# COMPUTE_CLUSTER_J7AHP0_CFG_WRAP_0_VBUSP4_CFG_AW4_CFG_MSMC1_ECC0 register map
Vendor: Texas Instruments
Peripheral module from a debugger description file (folder J7_AHP).
Registers are 32-bit, access not given, reset 0x0 unless marked. A register's access mark holds for its fields unless they carry their own. Offsets are as the file gives them; lines under a group give offsets from that group; [hi:lo] are bit positions; {n}, {i} and the like mark numbered series; 'fields as' and 'values as' point back to an identical list; <NAME> marks a mode.

## COMPUTE_CLUSTER_J7AHP0_CFG_WRAP_0_VBUSP4_CFG_AW4_CFG_MSMC1_ECC0
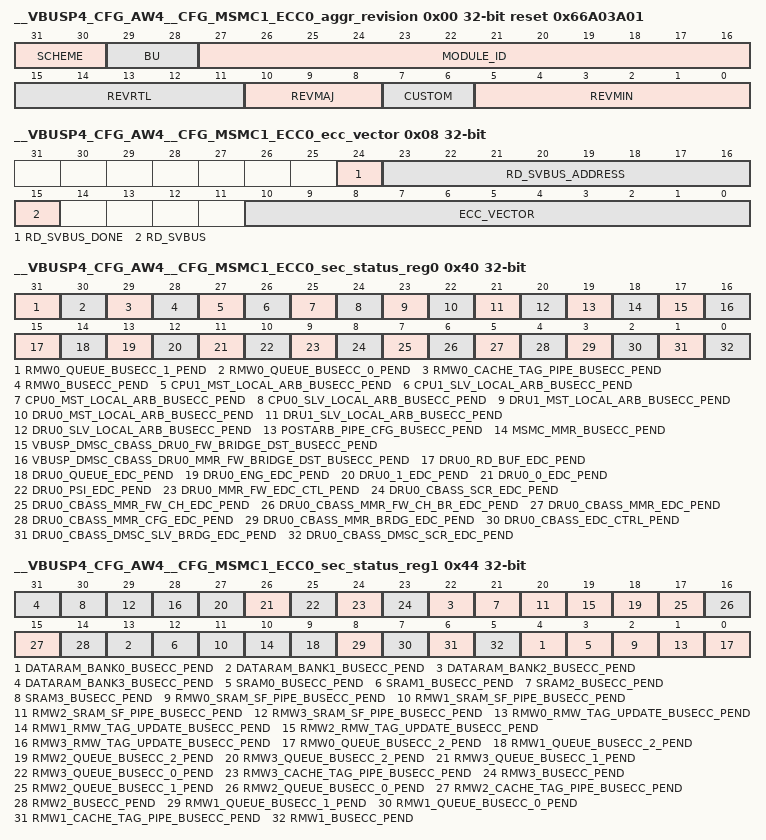
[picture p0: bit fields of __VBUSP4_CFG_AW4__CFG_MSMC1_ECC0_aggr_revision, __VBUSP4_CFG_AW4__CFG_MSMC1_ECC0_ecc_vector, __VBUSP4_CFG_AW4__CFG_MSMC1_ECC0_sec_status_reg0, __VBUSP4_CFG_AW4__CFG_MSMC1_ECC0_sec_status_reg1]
0x00 __VBUSP4_CFG_AW4__CFG_MSMC1_ECC0_aggr_revision ro reset 0x66A03A01
  [31:30] SCHEME
  [29:28] BU
  [27:16] MODULE_ID
  [15:11] REVRTL — RTL version
  [10:8] REVMAJ — Major version
  [7:6] CUSTOM — Custom version
  [5:0] REVMIN — Minor version
0x08 __VBUSP4_CFG_AW4__CFG_MSMC1_ECC0_ecc_vector
  [24] RD_SVBUS_DONE — Status to indicate if read on serial VBUS is complete, write of any value will clear this bit. (access R/W1TC)
  [23:16] RD_SVBUS_ADDRESS rw — Read address
  [15] RD_SVBUS — Write 1 to trigger a read on the serial VBUS (access R/W1TS)
  [10:0] ECC_VECTOR rw — Value written to select the corresponding ECC RAM for control or status
0x0C __VBUSP4_CFG_AW4__CFG_MSMC1_ECC0_misc_status ro reset 0x44
  [10:0] NUM_RAMS — Indicates the number of RAMS serviced by the ECC aggregator
0x10 __VBUSP4_CFG_AW4__CFG_MSMC1_ECC0_reserved_svbus rw
  [31:0] DATA — Serial VBUS register data
0x3C __VBUSP4_CFG_AW4__CFG_MSMC1_ECC0_sec_eoi_reg
  [0] EOI_WR — EOI Register (access R/W1TS)
0x40 __VBUSP4_CFG_AW4__CFG_MSMC1_ECC0_sec_status_reg0
  [31] RMW0_QUEUE_BUSECC_1_PEND — Interrupt Pending Status for rmw0_queue_busecc_1_pend (access R/W1TS)
  [30] RMW0_QUEUE_BUSECC_0_PEND — Interrupt Pending Status for rmw0_queue_busecc_0_pend (access R/W1TS)
  [29] RMW0_CACHE_TAG_PIPE_BUSECC_PEND — Interrupt Pending Status for rmw0_cache_tag_pipe_busecc_pend (access R/W1TS)
  [28] RMW0_BUSECC_PEND — Interrupt Pending Status for rmw0_busecc_pend (access R/W1TS)
  [27] CPU1_MST_LOCAL_ARB_BUSECC_PEND — Interrupt Pending Status for cpu1_mst_local_arb_busecc_pend (access R/W1TS)
  [26] CPU1_SLV_LOCAL_ARB_BUSECC_PEND — Interrupt Pending Status for cpu1_slv_local_arb_busecc_pend (access R/W1TS)
  [25] CPU0_MST_LOCAL_ARB_BUSECC_PEND — Interrupt Pending Status for cpu0_mst_local_arb_busecc_pend (access R/W1TS)
  [24] CPU0_SLV_LOCAL_ARB_BUSECC_PEND — Interrupt Pending Status for cpu0_slv_local_arb_busecc_pend (access R/W1TS)
  [23] DRU1_MST_LOCAL_ARB_BUSECC_PEND — Interrupt Pending Status for dru1_mst_local_arb_busecc_pend (access R/W1TS)
  [22] DRU0_MST_LOCAL_ARB_BUSECC_PEND — Interrupt Pending Status for dru0_mst_local_arb_busecc_pend (access R/W1TS)
  [21] DRU1_SLV_LOCAL_ARB_BUSECC_PEND — Interrupt Pending Status for dru1_slv_local_arb_busecc_pend (access R/W1TS)
  [20] DRU0_SLV_LOCAL_ARB_BUSECC_PEND — Interrupt Pending Status for dru0_slv_local_arb_busecc_pend (access R/W1TS)
  [19] POSTARB_PIPE_CFG_BUSECC_PEND — Interrupt Pending Status for postarb_pipe_cfg_busecc_pend (access R/W1TS)
  [18] MSMC_MMR_BUSECC_PEND — Interrupt Pending Status for msmc_mmr_busecc_pend (access R/W1TS)
  [17] VBUSP_DMSC_CBASS_DRU0_FW_BRIDGE_DST_BUSECC_PEND — Interrupt Pending Status for vbusp_dmsc_cbass_dru0_fw_bridge_dst_busecc_pend (access R/W1TS)
  [16] VBUSP_DMSC_CBASS_DRU0_MMR_FW_BRIDGE_DST_BUSECC_PEND — Interrupt Pending Status for vbusp_dmsc_cbass_dru0_mmr_fw_bridge_dst_busecc_pend (access R/W1TS)
  [15] DRU0_RD_BUF_EDC_PEND — Interrupt Pending Status for dru0_rd_buf_edc_pend (access R/W1TS)
  [14] DRU0_QUEUE_EDC_PEND — Interrupt Pending Status for dru0_queue_edc_pend (access R/W1TS)
  [13] DRU0_ENG_EDC_PEND — Interrupt Pending Status for dru0_eng_edc_pend (access R/W1TS)
  [12] DRU0_1_EDC_PEND — Interrupt Pending Status for dru0_1_edc_pend (access R/W1TS)
  [11] DRU0_0_EDC_PEND — Interrupt Pending Status for dru0_0_edc_pend (access R/W1TS)
  [10] DRU0_PSI_EDC_PEND — Interrupt Pending Status for dru0_psi_edc_pend (access R/W1TS)
  [9] DRU0_MMR_FW_EDC_CTL_PEND — Interrupt Pending Status for dru0_mmr_fw_edc_ctl_pend (access R/W1TS)
  [8] DRU0_CBASS_SCR_EDC_PEND — Interrupt Pending Status for dru0_cbass_scr_edc_pend (access R/W1TS)
  [7] DRU0_CBASS_MMR_FW_CH_EDC_PEND — Interrupt Pending Status for dru0_cbass_mmr_fw_ch_edc_pend (access R/W1TS)
  [6] DRU0_CBASS_MMR_FW_CH_BR_EDC_PEND — Interrupt Pending Status for dru0_cbass_mmr_fw_ch_br_edc_pend (access R/W1TS)
  [5] DRU0_CBASS_MMR_EDC_PEND — Interrupt Pending Status for dru0_cbass_mmr_edc_pend (access R/W1TS)
  [4] DRU0_CBASS_MMR_CFG_EDC_PEND — Interrupt Pending Status for dru0_cbass_mmr_cfg_edc_pend (access R/W1TS)
  [3] DRU0_CBASS_MMR_BRDG_EDC_PEND — Interrupt Pending Status for dru0_cbass_mmr_brdg_edc_pend (access R/W1TS)
  [2] DRU0_CBASS_EDC_CTRL_PEND — Interrupt Pending Status for dru0_cbass_edc_ctrl_pend (access R/W1TS)
  [1] DRU0_CBASS_DMSC_SLV_BRDG_EDC_PEND — Interrupt Pending Status for dru0_cbass_dmsc_slv_brdg_edc_pend (access R/W1TS)
  [0] DRU0_CBASS_DMSC_SCR_EDC_PEND — Interrupt Pending Status for dru0_cbass_dmsc_scr_edc_pend (access R/W1TS)
0x44 __VBUSP4_CFG_AW4__CFG_MSMC1_ECC0_sec_status_reg1
  [9n+4] DATARAM_BANK{n}_BUSECC_PEND (n=0..3) — Interrupt Pending Status for dataram_bank{n}_busecc_pend (access R/W1TS)
  [9n+3] SRAM{n}_BUSECC_PEND (n=0..3) — Interrupt Pending Status for sram{n}_busecc_pend (access R/W1TS)
  [9n+2] RMW{n}_SRAM_SF_PIPE_BUSECC_PEND (n=0..3) — Interrupt Pending Status for rmw{n}_sram_sf_pipe_busecc_pend (access R/W1TS)
  [9n+1] RMW{n}_RMW_TAG_UPDATE_BUSECC_PEND (n=0..3) — Interrupt Pending Status for rmw{n}_rmw_tag_update_busecc_pend (access R/W1TS)
  [9n] RMW{n}_QUEUE_BUSECC_2_PEND (n=0..3) — Interrupt Pending Status for rmw{n}_queue_busecc_2_pend (access R/W1TS)
  [26] RMW3_QUEUE_BUSECC_1_PEND — Interrupt Pending Status for rmw3_queue_busecc_1_pend (access R/W1TS)
  [25] RMW3_QUEUE_BUSECC_0_PEND — Interrupt Pending Status for rmw3_queue_busecc_0_pend (access R/W1TS)
  [24] RMW3_CACHE_TAG_PIPE_BUSECC_PEND — Interrupt Pending Status for rmw3_cache_tag_pipe_busecc_pend (access R/W1TS)
  [23] RMW3_BUSECC_PEND — Interrupt Pending Status for rmw3_busecc_pend (access R/W1TS)
  [17] RMW2_QUEUE_BUSECC_1_PEND — Interrupt Pending Status for rmw2_queue_busecc_1_pend (access R/W1TS)
  [16] RMW2_QUEUE_BUSECC_0_PEND — Interrupt Pending Status for rmw2_queue_busecc_0_pend (access R/W1TS)
  [15] RMW2_CACHE_TAG_PIPE_BUSECC_PEND — Interrupt Pending Status for rmw2_cache_tag_pipe_busecc_pend (access R/W1TS)
  [14] RMW2_BUSECC_PEND — Interrupt Pending Status for rmw2_busecc_pend (access R/W1TS)
  [8] RMW1_QUEUE_BUSECC_1_PEND — Interrupt Pending Status for rmw1_queue_busecc_1_pend (access R/W1TS)
  [7] RMW1_QUEUE_BUSECC_0_PEND — Interrupt Pending Status for rmw1_queue_busecc_0_pend (access R/W1TS)
  [6] RMW1_CACHE_TAG_PIPE_BUSECC_PEND — Interrupt Pending Status for rmw1_cache_tag_pipe_busecc_pend (access R/W1TS)
  [5] RMW1_BUSECC_PEND — Interrupt Pending Status for rmw1_busecc_pend (access R/W1TS)
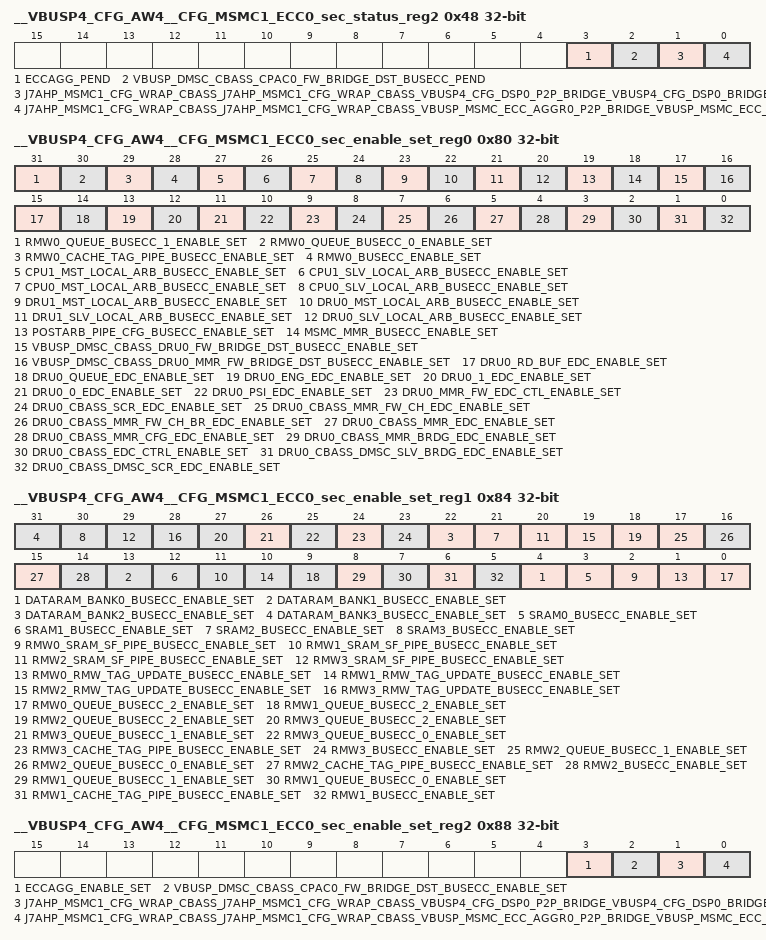
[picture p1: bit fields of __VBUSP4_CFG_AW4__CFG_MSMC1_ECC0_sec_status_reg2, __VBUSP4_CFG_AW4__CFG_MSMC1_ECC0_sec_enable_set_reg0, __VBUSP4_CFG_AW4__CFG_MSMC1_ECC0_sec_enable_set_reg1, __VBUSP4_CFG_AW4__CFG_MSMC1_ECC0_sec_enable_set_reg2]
0x48 __VBUSP4_CFG_AW4__CFG_MSMC1_ECC0_sec_status_reg2
  [3] ECCAGG_PEND — Interrupt Pending Status for eccagg_pend (access R/W1TS)
  [2] VBUSP_DMSC_CBASS_CPAC0_FW_BRIDGE_DST_BUSECC_PEND — Interrupt Pending Status for vbusp_dmsc_cbass_cpac0_fw_bridge_dst_busecc_pend (access R/W1TS)
  [1] J7AHP_MSMC1_CFG_WRAP_CBASS_J7AHP_MSMC1_CFG_WRAP_CBASS_VBUSP4_CFG_DSP0_P2P_BRIDGE_VBUSP4_CFG_DSP0_BRIDGE_DST_BUSECC_PEND — Interrupt Pending Status for j7ahp_msmc1_cfg_wrap_cbass_j7ahp_msmc1_cfg_wrap_cbass_vbusp4_cfg_dsp0_p2p_bridge_vbusp4_cfg_dsp0_bridge_dst_busecc_pend (access R/W1TS)
  [0] J7AHP_MSMC1_CFG_WRAP_CBASS_J7AHP_MSMC1_CFG_WRAP_CBASS_VBUSP_MSMC_ECC_AGGR0_P2P_BRIDGE_VBUSP_MSMC_ECC_AGGR0_BRIDGE_DST_BUSECC_PEND — Interrupt Pending Status for j7ahp_msmc1_cfg_wrap_cbass_j7ahp_msmc1_cfg_wrap_cbass_vbusp_msmc_ecc_aggr0_p2p_bridge_vbusp_msmc_ecc_aggr0_bridge_dst_busecc_pend (access R/W1TS)
0x80 __VBUSP4_CFG_AW4__CFG_MSMC1_ECC0_sec_enable_set_reg0
  [31] RMW0_QUEUE_BUSECC_1_ENABLE_SET — Interrupt Enable Set Register for rmw0_queue_busecc_1_pend (access R/W1TS)
  [30] RMW0_QUEUE_BUSECC_0_ENABLE_SET — Interrupt Enable Set Register for rmw0_queue_busecc_0_pend (access R/W1TS)
  [29] RMW0_CACHE_TAG_PIPE_BUSECC_ENABLE_SET — Interrupt Enable Set Register for rmw0_cache_tag_pipe_busecc_pend (access R/W1TS)
  [28] RMW0_BUSECC_ENABLE_SET — Interrupt Enable Set Register for rmw0_busecc_pend (access R/W1TS)
  [27] CPU1_MST_LOCAL_ARB_BUSECC_ENABLE_SET — Interrupt Enable Set Register for cpu1_mst_local_arb_busecc_pend (access R/W1TS)
  [26] CPU1_SLV_LOCAL_ARB_BUSECC_ENABLE_SET — Interrupt Enable Set Register for cpu1_slv_local_arb_busecc_pend (access R/W1TS)
  [25] CPU0_MST_LOCAL_ARB_BUSECC_ENABLE_SET — Interrupt Enable Set Register for cpu0_mst_local_arb_busecc_pend (access R/W1TS)
  [24] CPU0_SLV_LOCAL_ARB_BUSECC_ENABLE_SET — Interrupt Enable Set Register for cpu0_slv_local_arb_busecc_pend (access R/W1TS)
  [23] DRU1_MST_LOCAL_ARB_BUSECC_ENABLE_SET — Interrupt Enable Set Register for dru1_mst_local_arb_busecc_pend (access R/W1TS)
  [22] DRU0_MST_LOCAL_ARB_BUSECC_ENABLE_SET — Interrupt Enable Set Register for dru0_mst_local_arb_busecc_pend (access R/W1TS)
  [21] DRU1_SLV_LOCAL_ARB_BUSECC_ENABLE_SET — Interrupt Enable Set Register for dru1_slv_local_arb_busecc_pend (access R/W1TS)
  [20] DRU0_SLV_LOCAL_ARB_BUSECC_ENABLE_SET — Interrupt Enable Set Register for dru0_slv_local_arb_busecc_pend (access R/W1TS)
  [19] POSTARB_PIPE_CFG_BUSECC_ENABLE_SET — Interrupt Enable Set Register for postarb_pipe_cfg_busecc_pend (access R/W1TS)
  [18] MSMC_MMR_BUSECC_ENABLE_SET — Interrupt Enable Set Register for msmc_mmr_busecc_pend (access R/W1TS)
  [17] VBUSP_DMSC_CBASS_DRU0_FW_BRIDGE_DST_BUSECC_ENABLE_SET — Interrupt Enable Set Register for vbusp_dmsc_cbass_dru0_fw_bridge_dst_busecc_pend (access R/W1TS)
  [16] VBUSP_DMSC_CBASS_DRU0_MMR_FW_BRIDGE_DST_BUSECC_ENABLE_SET — Interrupt Enable Set Register for vbusp_dmsc_cbass_dru0_mmr_fw_bridge_dst_busecc_pend (access R/W1TS)
  [15] DRU0_RD_BUF_EDC_ENABLE_SET — Interrupt Enable Set Register for dru0_rd_buf_edc_pend (access R/W1TS)
  [14] DRU0_QUEUE_EDC_ENABLE_SET — Interrupt Enable Set Register for dru0_queue_edc_pend (access R/W1TS)
  [13] DRU0_ENG_EDC_ENABLE_SET — Interrupt Enable Set Register for dru0_eng_edc_pend (access R/W1TS)
  [12] DRU0_1_EDC_ENABLE_SET — Interrupt Enable Set Register for dru0_1_edc_pend (access R/W1TS)
  [11] DRU0_0_EDC_ENABLE_SET — Interrupt Enable Set Register for dru0_0_edc_pend (access R/W1TS)
  [10] DRU0_PSI_EDC_ENABLE_SET — Interrupt Enable Set Register for dru0_psi_edc_pend (access R/W1TS)
  [9] DRU0_MMR_FW_EDC_CTL_ENABLE_SET — Interrupt Enable Set Register for dru0_mmr_fw_edc_ctl_pend (access R/W1TS)
  [8] DRU0_CBASS_SCR_EDC_ENABLE_SET — Interrupt Enable Set Register for dru0_cbass_scr_edc_pend (access R/W1TS)
  [7] DRU0_CBASS_MMR_FW_CH_EDC_ENABLE_SET — Interrupt Enable Set Register for dru0_cbass_mmr_fw_ch_edc_pend (access R/W1TS)
  [6] DRU0_CBASS_MMR_FW_CH_BR_EDC_ENABLE_SET — Interrupt Enable Set Register for dru0_cbass_mmr_fw_ch_br_edc_pend (access R/W1TS)
  [5] DRU0_CBASS_MMR_EDC_ENABLE_SET — Interrupt Enable Set Register for dru0_cbass_mmr_edc_pend (access R/W1TS)
  [4] DRU0_CBASS_MMR_CFG_EDC_ENABLE_SET — Interrupt Enable Set Register for dru0_cbass_mmr_cfg_edc_pend (access R/W1TS)
  [3] DRU0_CBASS_MMR_BRDG_EDC_ENABLE_SET — Interrupt Enable Set Register for dru0_cbass_mmr_brdg_edc_pend (access R/W1TS)
  [2] DRU0_CBASS_EDC_CTRL_ENABLE_SET — Interrupt Enable Set Register for dru0_cbass_edc_ctrl_pend (access R/W1TS)
  [1] DRU0_CBASS_DMSC_SLV_BRDG_EDC_ENABLE_SET — Interrupt Enable Set Register for dru0_cbass_dmsc_slv_brdg_edc_pend (access R/W1TS)
  [0] DRU0_CBASS_DMSC_SCR_EDC_ENABLE_SET — Interrupt Enable Set Register for dru0_cbass_dmsc_scr_edc_pend (access R/W1TS)
0x84 __VBUSP4_CFG_AW4__CFG_MSMC1_ECC0_sec_enable_set_reg1
  [9n+4] DATARAM_BANK{n}_BUSECC_ENABLE_SET (n=0..3) — Interrupt Enable Set Register for dataram_bank{n}_busecc_pend (access R/W1TS)
  [9n+3] SRAM{n}_BUSECC_ENABLE_SET (n=0..3) — Interrupt Enable Set Register for sram{n}_busecc_pend (access R/W1TS)
  [9n+2] RMW{n}_SRAM_SF_PIPE_BUSECC_ENABLE_SET (n=0..3) — Interrupt Enable Set Register for rmw{n}_sram_sf_pipe_busecc_pend (access R/W1TS)
  [9n+1] RMW{n}_RMW_TAG_UPDATE_BUSECC_ENABLE_SET (n=0..3) — Interrupt Enable Set Register for rmw{n}_rmw_tag_update_busecc_pend (access R/W1TS)
  [9n] RMW{n}_QUEUE_BUSECC_2_ENABLE_SET (n=0..3) — Interrupt Enable Set Register for rmw{n}_queue_busecc_2_pend (access R/W1TS)
  [26] RMW3_QUEUE_BUSECC_1_ENABLE_SET — Interrupt Enable Set Register for rmw3_queue_busecc_1_pend (access R/W1TS)
  [25] RMW3_QUEUE_BUSECC_0_ENABLE_SET — Interrupt Enable Set Register for rmw3_queue_busecc_0_pend (access R/W1TS)
  [24] RMW3_CACHE_TAG_PIPE_BUSECC_ENABLE_SET — Interrupt Enable Set Register for rmw3_cache_tag_pipe_busecc_pend (access R/W1TS)
  [23] RMW3_BUSECC_ENABLE_SET — Interrupt Enable Set Register for rmw3_busecc_pend (access R/W1TS)
  [17] RMW2_QUEUE_BUSECC_1_ENABLE_SET — Interrupt Enable Set Register for rmw2_queue_busecc_1_pend (access R/W1TS)
  [16] RMW2_QUEUE_BUSECC_0_ENABLE_SET — Interrupt Enable Set Register for rmw2_queue_busecc_0_pend (access R/W1TS)
  [15] RMW2_CACHE_TAG_PIPE_BUSECC_ENABLE_SET — Interrupt Enable Set Register for rmw2_cache_tag_pipe_busecc_pend (access R/W1TS)
  [14] RMW2_BUSECC_ENABLE_SET — Interrupt Enable Set Register for rmw2_busecc_pend (access R/W1TS)
  [8] RMW1_QUEUE_BUSECC_1_ENABLE_SET — Interrupt Enable Set Register for rmw1_queue_busecc_1_pend (access R/W1TS)
  [7] RMW1_QUEUE_BUSECC_0_ENABLE_SET — Interrupt Enable Set Register for rmw1_queue_busecc_0_pend (access R/W1TS)
  [6] RMW1_CACHE_TAG_PIPE_BUSECC_ENABLE_SET — Interrupt Enable Set Register for rmw1_cache_tag_pipe_busecc_pend (access R/W1TS)
  [5] RMW1_BUSECC_ENABLE_SET — Interrupt Enable Set Register for rmw1_busecc_pend (access R/W1TS)
0x88 __VBUSP4_CFG_AW4__CFG_MSMC1_ECC0_sec_enable_set_reg2
  [3] ECCAGG_ENABLE_SET — Interrupt Enable Set Register for eccagg_pend (access R/W1TS)
  [2] VBUSP_DMSC_CBASS_CPAC0_FW_BRIDGE_DST_BUSECC_ENABLE_SET — Interrupt Enable Set Register for vbusp_dmsc_cbass_cpac0_fw_bridge_dst_busecc_pend (access R/W1TS)
  [1] J7AHP_MSMC1_CFG_WRAP_CBASS_J7AHP_MSMC1_CFG_WRAP_CBASS_VBUSP4_CFG_DSP0_P2P_BRIDGE_VBUSP4_CFG_DSP0_BRIDGE_DST_BUSECC_ENABLE_SET — Interrupt Enable Set Register for j7ahp_msmc1_cfg_wrap_cbass_j7ahp_msmc1_cfg_wrap_cbass_vbusp4_cfg_dsp0_p2p_bridge_vbusp4_cfg_dsp0_bridge_dst_busecc_pend (access R/W1TS)
  [0] J7AHP_MSMC1_CFG_WRAP_CBASS_J7AHP_MSMC1_CFG_WRAP_CBASS_VBUSP_MSMC_ECC_AGGR0_P2P_BRIDGE_VBUSP_MSMC_ECC_AGGR0_BRIDGE_DST_BUSECC_ENABLE_SET — Interrupt Enable Set Register for j7ahp_msmc1_cfg_wrap_cbass_j7ahp_msmc1_cfg_wrap_cbass_vbusp_msmc_ecc_aggr0_p2p_bridge_vbusp_msmc_ecc_aggr0_bridge_dst_busecc_pend (access R/W1TS)
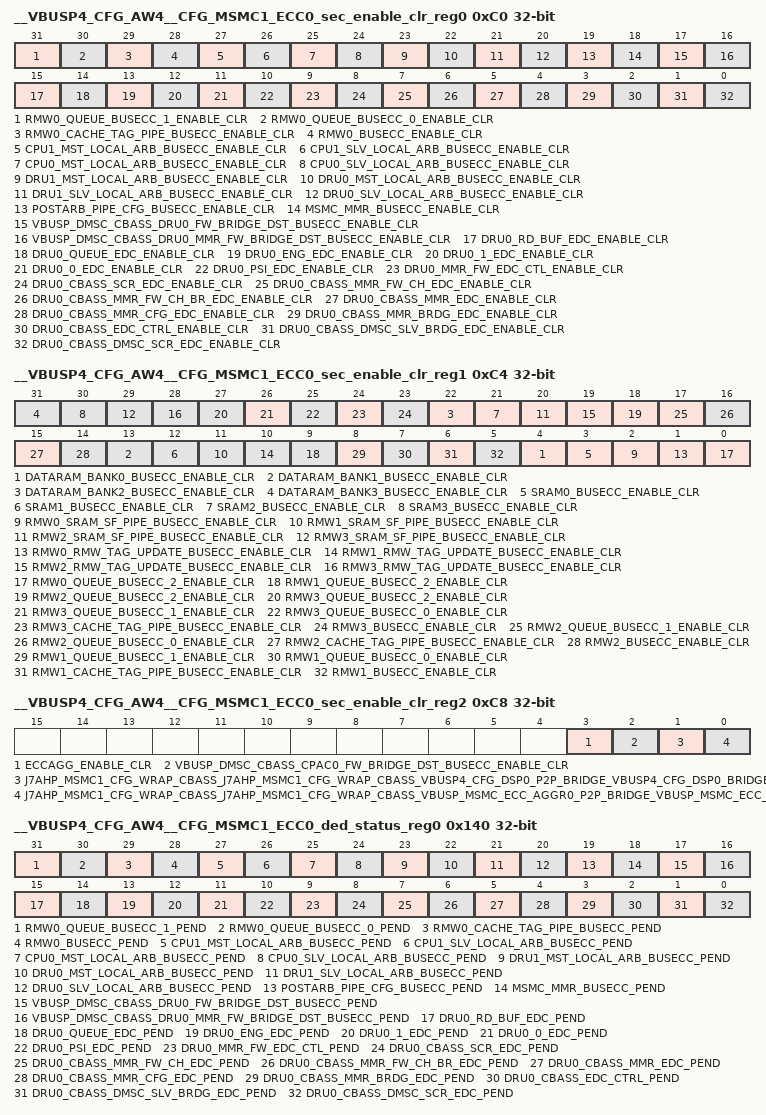
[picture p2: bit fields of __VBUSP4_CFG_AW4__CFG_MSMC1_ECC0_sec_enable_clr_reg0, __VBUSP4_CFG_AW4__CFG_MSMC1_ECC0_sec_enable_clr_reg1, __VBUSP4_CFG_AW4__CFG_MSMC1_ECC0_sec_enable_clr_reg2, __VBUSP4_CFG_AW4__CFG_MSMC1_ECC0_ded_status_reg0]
0xC0 __VBUSP4_CFG_AW4__CFG_MSMC1_ECC0_sec_enable_clr_reg0
  [31] RMW0_QUEUE_BUSECC_1_ENABLE_CLR — Interrupt Enable Clear Register for rmw0_queue_busecc_1_pend (access R/W1TC)
  [30] RMW0_QUEUE_BUSECC_0_ENABLE_CLR — Interrupt Enable Clear Register for rmw0_queue_busecc_0_pend (access R/W1TC)
  [29] RMW0_CACHE_TAG_PIPE_BUSECC_ENABLE_CLR — Interrupt Enable Clear Register for rmw0_cache_tag_pipe_busecc_pend (access R/W1TC)
  [28] RMW0_BUSECC_ENABLE_CLR — Interrupt Enable Clear Register for rmw0_busecc_pend (access R/W1TC)
  [27] CPU1_MST_LOCAL_ARB_BUSECC_ENABLE_CLR — Interrupt Enable Clear Register for cpu1_mst_local_arb_busecc_pend (access R/W1TC)
  [26] CPU1_SLV_LOCAL_ARB_BUSECC_ENABLE_CLR — Interrupt Enable Clear Register for cpu1_slv_local_arb_busecc_pend (access R/W1TC)
  [25] CPU0_MST_LOCAL_ARB_BUSECC_ENABLE_CLR — Interrupt Enable Clear Register for cpu0_mst_local_arb_busecc_pend (access R/W1TC)
  [24] CPU0_SLV_LOCAL_ARB_BUSECC_ENABLE_CLR — Interrupt Enable Clear Register for cpu0_slv_local_arb_busecc_pend (access R/W1TC)
  [23] DRU1_MST_LOCAL_ARB_BUSECC_ENABLE_CLR — Interrupt Enable Clear Register for dru1_mst_local_arb_busecc_pend (access R/W1TC)
  [22] DRU0_MST_LOCAL_ARB_BUSECC_ENABLE_CLR — Interrupt Enable Clear Register for dru0_mst_local_arb_busecc_pend (access R/W1TC)
  [21] DRU1_SLV_LOCAL_ARB_BUSECC_ENABLE_CLR — Interrupt Enable Clear Register for dru1_slv_local_arb_busecc_pend (access R/W1TC)
  [20] DRU0_SLV_LOCAL_ARB_BUSECC_ENABLE_CLR — Interrupt Enable Clear Register for dru0_slv_local_arb_busecc_pend (access R/W1TC)
  [19] POSTARB_PIPE_CFG_BUSECC_ENABLE_CLR — Interrupt Enable Clear Register for postarb_pipe_cfg_busecc_pend (access R/W1TC)
  [18] MSMC_MMR_BUSECC_ENABLE_CLR — Interrupt Enable Clear Register for msmc_mmr_busecc_pend (access R/W1TC)
  [17] VBUSP_DMSC_CBASS_DRU0_FW_BRIDGE_DST_BUSECC_ENABLE_CLR — Interrupt Enable Clear Register for vbusp_dmsc_cbass_dru0_fw_bridge_dst_busecc_pend (access R/W1TC)
  [16] VBUSP_DMSC_CBASS_DRU0_MMR_FW_BRIDGE_DST_BUSECC_ENABLE_CLR — Interrupt Enable Clear Register for vbusp_dmsc_cbass_dru0_mmr_fw_bridge_dst_busecc_pend (access R/W1TC)
  [15] DRU0_RD_BUF_EDC_ENABLE_CLR — Interrupt Enable Clear Register for dru0_rd_buf_edc_pend (access R/W1TC)
  [14] DRU0_QUEUE_EDC_ENABLE_CLR — Interrupt Enable Clear Register for dru0_queue_edc_pend (access R/W1TC)
  [13] DRU0_ENG_EDC_ENABLE_CLR — Interrupt Enable Clear Register for dru0_eng_edc_pend (access R/W1TC)
  [12] DRU0_1_EDC_ENABLE_CLR — Interrupt Enable Clear Register for dru0_1_edc_pend (access R/W1TC)
  [11] DRU0_0_EDC_ENABLE_CLR — Interrupt Enable Clear Register for dru0_0_edc_pend (access R/W1TC)
  [10] DRU0_PSI_EDC_ENABLE_CLR — Interrupt Enable Clear Register for dru0_psi_edc_pend (access R/W1TC)
  [9] DRU0_MMR_FW_EDC_CTL_ENABLE_CLR — Interrupt Enable Clear Register for dru0_mmr_fw_edc_ctl_pend (access R/W1TC)
  [8] DRU0_CBASS_SCR_EDC_ENABLE_CLR — Interrupt Enable Clear Register for dru0_cbass_scr_edc_pend (access R/W1TC)
  [7] DRU0_CBASS_MMR_FW_CH_EDC_ENABLE_CLR — Interrupt Enable Clear Register for dru0_cbass_mmr_fw_ch_edc_pend (access R/W1TC)
  [6] DRU0_CBASS_MMR_FW_CH_BR_EDC_ENABLE_CLR — Interrupt Enable Clear Register for dru0_cbass_mmr_fw_ch_br_edc_pend (access R/W1TC)
  [5] DRU0_CBASS_MMR_EDC_ENABLE_CLR — Interrupt Enable Clear Register for dru0_cbass_mmr_edc_pend (access R/W1TC)
  [4] DRU0_CBASS_MMR_CFG_EDC_ENABLE_CLR — Interrupt Enable Clear Register for dru0_cbass_mmr_cfg_edc_pend (access R/W1TC)
  [3] DRU0_CBASS_MMR_BRDG_EDC_ENABLE_CLR — Interrupt Enable Clear Register for dru0_cbass_mmr_brdg_edc_pend (access R/W1TC)
  [2] DRU0_CBASS_EDC_CTRL_ENABLE_CLR — Interrupt Enable Clear Register for dru0_cbass_edc_ctrl_pend (access R/W1TC)
  [1] DRU0_CBASS_DMSC_SLV_BRDG_EDC_ENABLE_CLR — Interrupt Enable Clear Register for dru0_cbass_dmsc_slv_brdg_edc_pend (access R/W1TC)
  [0] DRU0_CBASS_DMSC_SCR_EDC_ENABLE_CLR — Interrupt Enable Clear Register for dru0_cbass_dmsc_scr_edc_pend (access R/W1TC)
0xC4 __VBUSP4_CFG_AW4__CFG_MSMC1_ECC0_sec_enable_clr_reg1
  [9n+4] DATARAM_BANK{n}_BUSECC_ENABLE_CLR (n=0..3) — Interrupt Enable Clear Register for dataram_bank{n}_busecc_pend (access R/W1TC)
  [9n+3] SRAM{n}_BUSECC_ENABLE_CLR (n=0..3) — Interrupt Enable Clear Register for sram{n}_busecc_pend (access R/W1TC)
  [9n+2] RMW{n}_SRAM_SF_PIPE_BUSECC_ENABLE_CLR (n=0..3) — Interrupt Enable Clear Register for rmw{n}_sram_sf_pipe_busecc_pend (access R/W1TC)
  [9n+1] RMW{n}_RMW_TAG_UPDATE_BUSECC_ENABLE_CLR (n=0..3) — Interrupt Enable Clear Register for rmw{n}_rmw_tag_update_busecc_pend (access R/W1TC)
  [9n] RMW{n}_QUEUE_BUSECC_2_ENABLE_CLR (n=0..3) — Interrupt Enable Clear Register for rmw{n}_queue_busecc_2_pend (access R/W1TC)
  [26] RMW3_QUEUE_BUSECC_1_ENABLE_CLR — Interrupt Enable Clear Register for rmw3_queue_busecc_1_pend (access R/W1TC)
  [25] RMW3_QUEUE_BUSECC_0_ENABLE_CLR — Interrupt Enable Clear Register for rmw3_queue_busecc_0_pend (access R/W1TC)
  [24] RMW3_CACHE_TAG_PIPE_BUSECC_ENABLE_CLR — Interrupt Enable Clear Register for rmw3_cache_tag_pipe_busecc_pend (access R/W1TC)
  [23] RMW3_BUSECC_ENABLE_CLR — Interrupt Enable Clear Register for rmw3_busecc_pend (access R/W1TC)
  [17] RMW2_QUEUE_BUSECC_1_ENABLE_CLR — Interrupt Enable Clear Register for rmw2_queue_busecc_1_pend (access R/W1TC)
  [16] RMW2_QUEUE_BUSECC_0_ENABLE_CLR — Interrupt Enable Clear Register for rmw2_queue_busecc_0_pend (access R/W1TC)
  [15] RMW2_CACHE_TAG_PIPE_BUSECC_ENABLE_CLR — Interrupt Enable Clear Register for rmw2_cache_tag_pipe_busecc_pend (access R/W1TC)
  [14] RMW2_BUSECC_ENABLE_CLR — Interrupt Enable Clear Register for rmw2_busecc_pend (access R/W1TC)
  [8] RMW1_QUEUE_BUSECC_1_ENABLE_CLR — Interrupt Enable Clear Register for rmw1_queue_busecc_1_pend (access R/W1TC)
  [7] RMW1_QUEUE_BUSECC_0_ENABLE_CLR — Interrupt Enable Clear Register for rmw1_queue_busecc_0_pend (access R/W1TC)
  [6] RMW1_CACHE_TAG_PIPE_BUSECC_ENABLE_CLR — Interrupt Enable Clear Register for rmw1_cache_tag_pipe_busecc_pend (access R/W1TC)
  [5] RMW1_BUSECC_ENABLE_CLR — Interrupt Enable Clear Register for rmw1_busecc_pend (access R/W1TC)
0xC8 __VBUSP4_CFG_AW4__CFG_MSMC1_ECC0_sec_enable_clr_reg2
  [3] ECCAGG_ENABLE_CLR — Interrupt Enable Clear Register for eccagg_pend (access R/W1TC)
  [2] VBUSP_DMSC_CBASS_CPAC0_FW_BRIDGE_DST_BUSECC_ENABLE_CLR — Interrupt Enable Clear Register for vbusp_dmsc_cbass_cpac0_fw_bridge_dst_busecc_pend (access R/W1TC)
  [1] J7AHP_MSMC1_CFG_WRAP_CBASS_J7AHP_MSMC1_CFG_WRAP_CBASS_VBUSP4_CFG_DSP0_P2P_BRIDGE_VBUSP4_CFG_DSP0_BRIDGE_DST_BUSECC_ENABLE_CLR — Interrupt Enable Clear Register for j7ahp_msmc1_cfg_wrap_cbass_j7ahp_msmc1_cfg_wrap_cbass_vbusp4_cfg_dsp0_p2p_bridge_vbusp4_cfg_dsp0_bridge_dst_busecc_pend (access R/W1TC)
  [0] J7AHP_MSMC1_CFG_WRAP_CBASS_J7AHP_MSMC1_CFG_WRAP_CBASS_VBUSP_MSMC_ECC_AGGR0_P2P_BRIDGE_VBUSP_MSMC_ECC_AGGR0_BRIDGE_DST_BUSECC_ENABLE_CLR — Interrupt Enable Clear Register for j7ahp_msmc1_cfg_wrap_cbass_j7ahp_msmc1_cfg_wrap_cbass_vbusp_msmc_ecc_aggr0_p2p_bridge_vbusp_msmc_ecc_aggr0_bridge_dst_busecc_pend (access R/W1TC)
0x13C __VBUSP4_CFG_AW4__CFG_MSMC1_ECC0_ded_eoi_reg
  [0] EOI_WR — EOI Register (access R/W1TS)
0x140 __VBUSP4_CFG_AW4__CFG_MSMC1_ECC0_ded_status_reg0
  fields as __VBUSP4_CFG_AW4__CFG_MSMC1_ECC0_sec_status_reg0
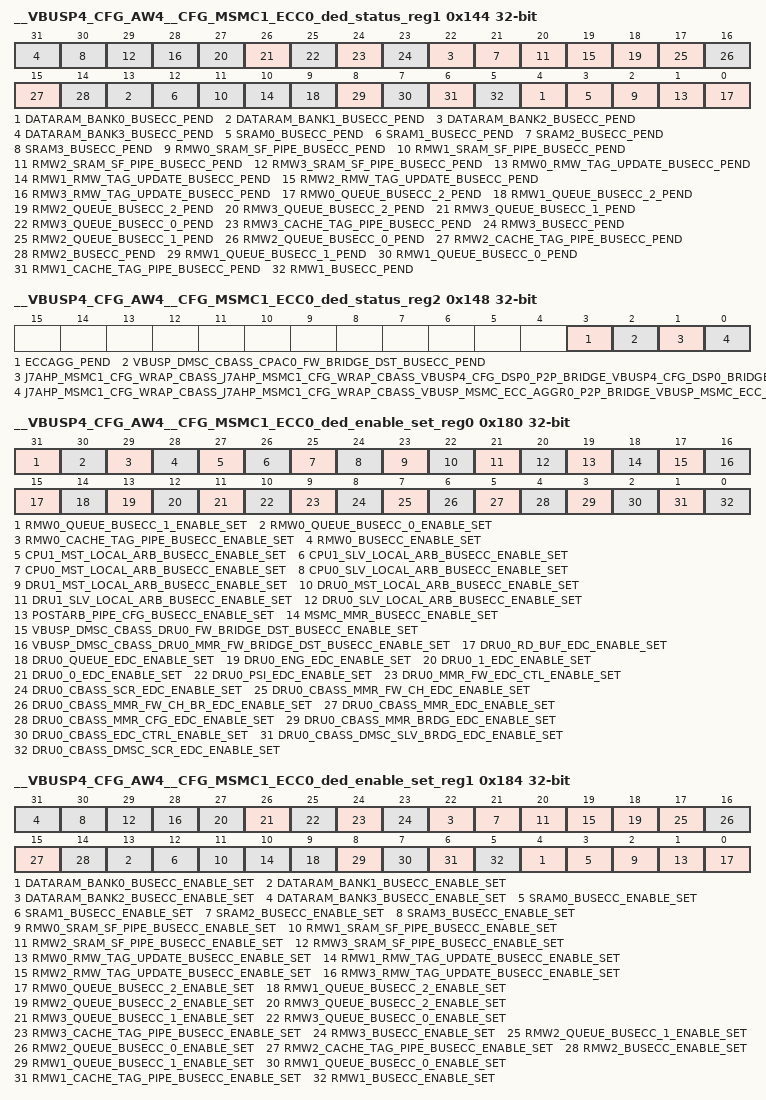
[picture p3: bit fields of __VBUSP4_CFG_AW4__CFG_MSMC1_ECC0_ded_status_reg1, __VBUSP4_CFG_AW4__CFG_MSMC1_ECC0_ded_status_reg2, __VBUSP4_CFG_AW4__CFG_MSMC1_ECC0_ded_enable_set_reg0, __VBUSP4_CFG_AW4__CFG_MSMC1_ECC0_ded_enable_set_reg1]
0x144 __VBUSP4_CFG_AW4__CFG_MSMC1_ECC0_ded_status_reg1
  fields as __VBUSP4_CFG_AW4__CFG_MSMC1_ECC0_sec_status_reg1
0x148 __VBUSP4_CFG_AW4__CFG_MSMC1_ECC0_ded_status_reg2
  fields as __VBUSP4_CFG_AW4__CFG_MSMC1_ECC0_sec_status_reg2
0x180 __VBUSP4_CFG_AW4__CFG_MSMC1_ECC0_ded_enable_set_reg0
  fields as __VBUSP4_CFG_AW4__CFG_MSMC1_ECC0_sec_enable_set_reg0
0x184 __VBUSP4_CFG_AW4__CFG_MSMC1_ECC0_ded_enable_set_reg1
  fields as __VBUSP4_CFG_AW4__CFG_MSMC1_ECC0_sec_enable_set_reg1
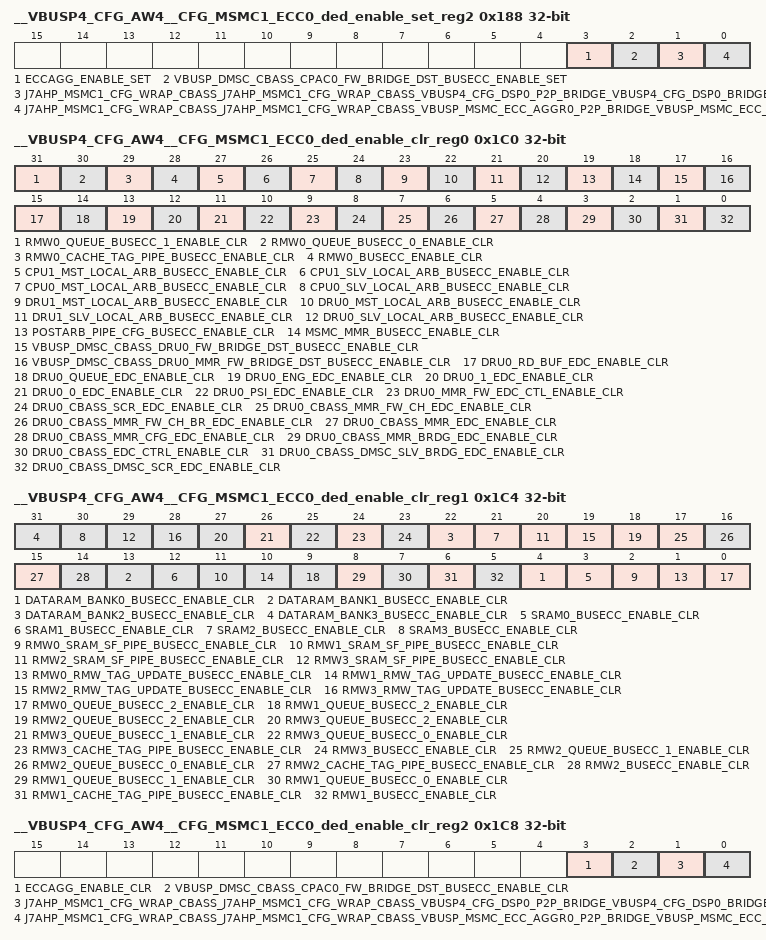
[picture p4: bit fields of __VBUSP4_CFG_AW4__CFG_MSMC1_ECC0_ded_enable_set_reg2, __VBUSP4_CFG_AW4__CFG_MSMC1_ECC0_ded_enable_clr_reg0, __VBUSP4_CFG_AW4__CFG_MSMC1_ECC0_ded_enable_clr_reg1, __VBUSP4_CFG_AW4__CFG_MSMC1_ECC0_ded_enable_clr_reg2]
0x188 __VBUSP4_CFG_AW4__CFG_MSMC1_ECC0_ded_enable_set_reg2
  fields as __VBUSP4_CFG_AW4__CFG_MSMC1_ECC0_sec_enable_set_reg2
0x1C0 __VBUSP4_CFG_AW4__CFG_MSMC1_ECC0_ded_enable_clr_reg0
  fields as __VBUSP4_CFG_AW4__CFG_MSMC1_ECC0_sec_enable_clr_reg0
0x1C4 __VBUSP4_CFG_AW4__CFG_MSMC1_ECC0_ded_enable_clr_reg1
  fields as __VBUSP4_CFG_AW4__CFG_MSMC1_ECC0_sec_enable_clr_reg1
0x1C8 __VBUSP4_CFG_AW4__CFG_MSMC1_ECC0_ded_enable_clr_reg2
  fields as __VBUSP4_CFG_AW4__CFG_MSMC1_ECC0_sec_enable_clr_reg2
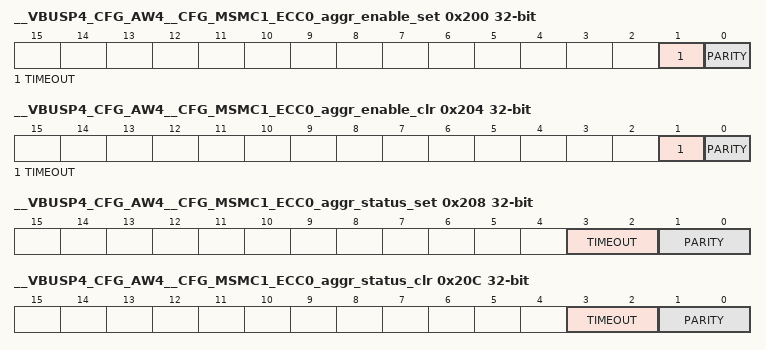
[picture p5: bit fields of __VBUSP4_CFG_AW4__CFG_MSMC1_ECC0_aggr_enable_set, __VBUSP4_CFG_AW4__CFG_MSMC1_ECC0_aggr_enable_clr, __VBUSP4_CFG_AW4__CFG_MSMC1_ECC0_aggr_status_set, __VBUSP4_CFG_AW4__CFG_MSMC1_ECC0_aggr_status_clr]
0x200 __VBUSP4_CFG_AW4__CFG_MSMC1_ECC0_aggr_enable_set
  [1] TIMEOUT — interrupt enable set for svbus timeout errors (access R/W1TS)
  [0] PARITY — interrupt enable set for parity errors (access R/W1TS)
0x204 __VBUSP4_CFG_AW4__CFG_MSMC1_ECC0_aggr_enable_clr
  [1] TIMEOUT — interrupt enable clear for svbus timeout errors (access R/W1TC)
  [0] PARITY — interrupt enable clear for parity errors (access R/W1TC)
0x208 __VBUSP4_CFG_AW4__CFG_MSMC1_ECC0_aggr_status_set
  [3:2] TIMEOUT — interrupt status set for svbus timeout errors (access R/WI)
  [1:0] PARITY — interrupt status set for parity errors (access R/WI)
0x20C __VBUSP4_CFG_AW4__CFG_MSMC1_ECC0_aggr_status_clr
  [3:2] TIMEOUT — interrupt status clear for svbus timeout errors (access R/WD)
  [1:0] PARITY — interrupt status clear for parity errors (access R/WD)
